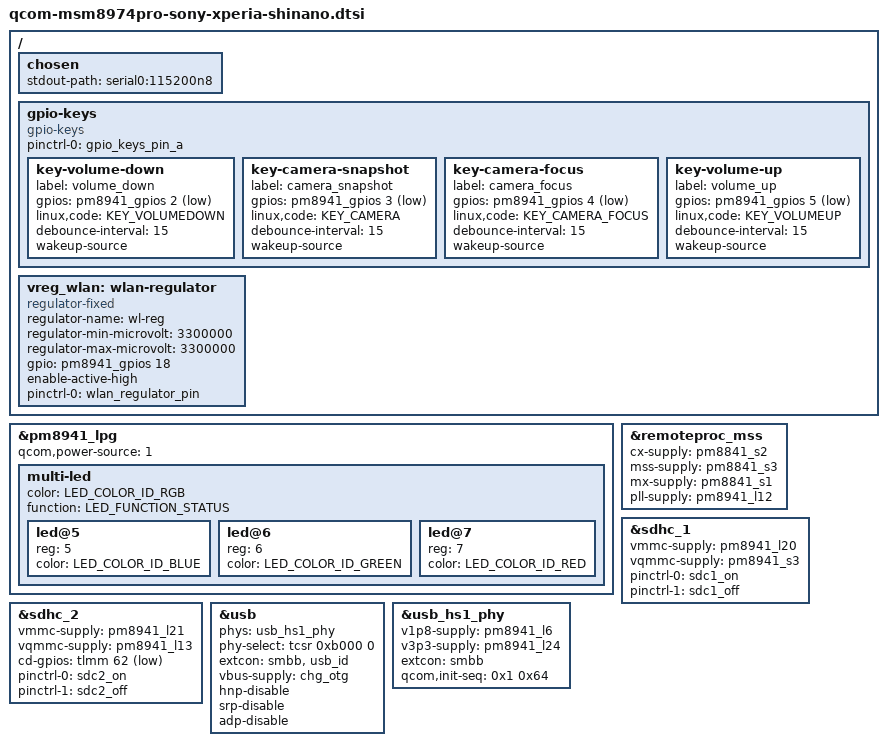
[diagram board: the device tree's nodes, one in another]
// SPDX-License-Identifier: GPL-2.0
#include "qcom-msm8974pro.dtsi"
#include "qcom-pm8841.dtsi"
#include "qcom-pm8941.dtsi"
#include <dt-bindings/input/input.h>
#include <dt-bindings/leds/common.h>
#include <dt-bindings/pinctrl/qcom,pmic-gpio.h>

/ {
	chosen {
		stdout-path = "serial0:115200n8";
	};

	gpio-keys {
		compatible = "gpio-keys";

		pinctrl-0 = <&gpio_keys_pin_a>;
		pinctrl-names = "default";

		key-volume-down {
			label = "volume_down";
			gpios = <&pm8941_gpios 2 GPIO_ACTIVE_LOW>;
			linux,code = <KEY_VOLUMEDOWN>;
			debounce-interval = <15>;
			wakeup-source;
		};

		key-camera-snapshot {
			label = "camera_snapshot";
			gpios = <&pm8941_gpios 3 GPIO_ACTIVE_LOW>;
			linux,code = <KEY_CAMERA>;
			debounce-interval = <15>;
			wakeup-source;
		};

		key-camera-focus {
			label = "camera_focus";
			gpios = <&pm8941_gpios 4 GPIO_ACTIVE_LOW>;
			linux,code = <KEY_CAMERA_FOCUS>;
			debounce-interval = <15>;
			wakeup-source;
		};

		key-volume-up {
			label = "volume_up";
			gpios = <&pm8941_gpios 5 GPIO_ACTIVE_LOW>;
			linux,code = <KEY_VOLUMEUP>;
			debounce-interval = <15>;
			wakeup-source;
		};
	};
	
	vreg_wlan: wlan-regulator {
		compatible = "regulator-fixed";

		regulator-name = "wl-reg";
		regulator-min-microvolt = <3300000>;
		regulator-max-microvolt = <3300000>;

		gpio = <&pm8941_gpios 18 GPIO_ACTIVE_HIGH>;
		enable-active-high;

		pinctrl-0 = <&wlan_regulator_pin>;
		pinctrl-names = "default";
	};
};

&pm8941_lpg {
	qcom,power-source = <1>;

	status = "okay";

	multi-led {
		color = <LED_COLOR_ID_RGB>;
		function = LED_FUNCTION_STATUS;

		#address-cells = <1>;
		#size-cells = <0>;

		led@5 {
			reg = <5>;
			color = <LED_COLOR_ID_BLUE>;
		};

		led@6 {
			reg = <6>;
			color = <LED_COLOR_ID_GREEN>;
		};

		led@7 {
			reg = <7>;
			color = <LED_COLOR_ID_RED>;
		};
	};
};

&remoteproc_mss {
	cx-supply = <&pm8841_s2>;
	mss-supply = <&pm8841_s3>;
	mx-supply = <&pm8841_s1>;
	pll-supply = <&pm8941_l12>;

	status = "okay";
};

&sdhc_1 {
	vmmc-supply = <&pm8941_l20>;
	vqmmc-supply = <&pm8941_s3>;

	pinctrl-0 = <&sdc1_on>;
	pinctrl-1 = <&sdc1_off>;
	pinctrl-names = "default", "sleep";

	status = "okay";
};

&sdhc_2 {
	vmmc-supply = <&pm8941_l21>;
	vqmmc-supply = <&pm8941_l13>;

	cd-gpios = <&tlmm 62 GPIO_ACTIVE_LOW>;

	pinctrl-0 = <&sdc2_on>;
	pinctrl-1 = <&sdc2_off>;
	pinctrl-names = "default", "sleep";

	status = "okay";
};


&usb {
	phys = <&usb_hs1_phy>;
	phy-select = <&tcsr 0xb000 0>;
	extcon = <&smbb>, <&usb_id>;
	vbus-supply = <&chg_otg>;

	hnp-disable;
	srp-disable;
	adp-disable;

	status = "okay";
};

&usb_hs1_phy {
	v1p8-supply = <&pm8941_l6>;
	v3p3-supply = <&pm8941_l24>;

	extcon = <&smbb>;
	qcom,init-seq = /bits/ 8 <0x1 0x64>;

	status = "okay";
};


